# SIMG301M104LIH register map
Vendor: Silicon Labs; Series: Si; File version: B
Registers are 32-bit, read-write, reset 0x0 unless marked. A register's access mark holds for its fields unless they carry their own. Offsets are from the block's base; [hi:lo] are bit positions.

## LPWAES_NS — LPWAES_NS Registers
Base 0x41004000
Same registers: SYMCRYPTO_NS 0x41000000, SYMCRYPTO_S 0x51000000, LPWAES_S 0x51004000
0x00 FETCHADDR — Fetcher: Start address of data block. In direct mode, this register is written by the software. In scatter-gather mode, this register is updated after each processed descriptor.
  [31:0] ADDR — Start address of data block
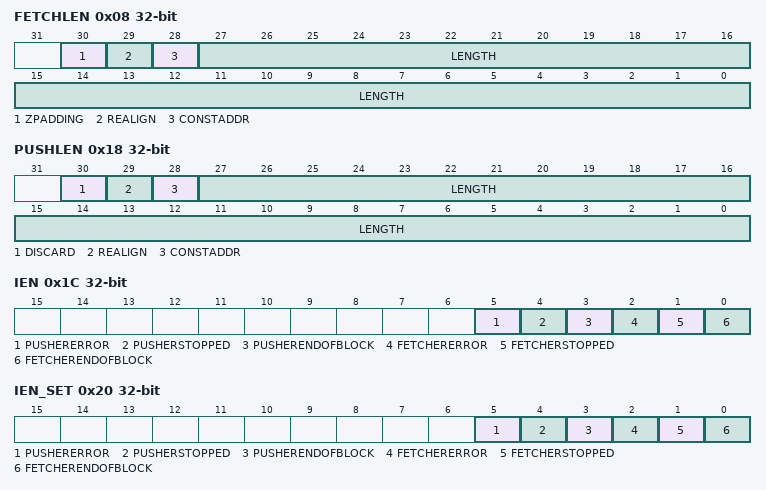
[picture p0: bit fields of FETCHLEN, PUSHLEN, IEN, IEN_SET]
0x08 FETCHLEN — Fetcher: Length of data block. In direct mode, this register is written by the software. In scatter-gather mode, this register is not used.
  [30] ZPADDING — Generate zeroes
  [29] REALIGN — Realign lengh
  [28] CONSTADDR — Constant address
  [27:0] LENGTH — Length of data block
0x0C FETCHTAG — Fetcher: User tag. In direct mode, this register is written by the software. In scatter-gather mode, this register is not used.
  [31:0] TAG — User tag
0x10 PUSHADDR — Pusher: Start address of data block (LSB). In direct mode, this register is written by the software. In scatter-gather mode, this register is updated after each processed descriptor.
  [31:0] ADDR — Start address of data block
0x18 PUSHLEN — Pusher: Length of data block. In direct mode, this register is written by the software. In scatter-gather mode, this register is not used.
  [30] DISCARD — Discard data
  [29] REALIGN — Realign length
  [28] CONSTADDR — Constant address
  [27:0] LENGTH — Start address of data block
0x1C IEN — Interrupt enable
  [5] PUSHERERROR — Error interrupt enable
  [4] PUSHERSTOPPED — Stopped interrupt enable
  [3] PUSHERENDOFBLOCK — End of block interrupt enable
  [2] FETCHERERROR — Error interrupt enable
  [1] FETCHERSTOPPED — Stopped interrupt enable
  [0] FETCHERENDOFBLOCK — End of block interrupt enable
0x20 IEN_SET wo — Set register for IEN. Writing a '1' enables the interrupt. Writing a '0' has no effect.
  [5] PUSHERERROR — Error interrupt enable set
  [4] PUSHERSTOPPED — Stopped interrupt enable set
  [3] PUSHERENDOFBLOCK — End of block interrupt enable set
  [2] FETCHERERROR — Error interrupt enable set
  [1] FETCHERSTOPPED — Stopped interrupt enable set
  [0] FETCHERENDOFBLOCK — End of block interrupt enable set
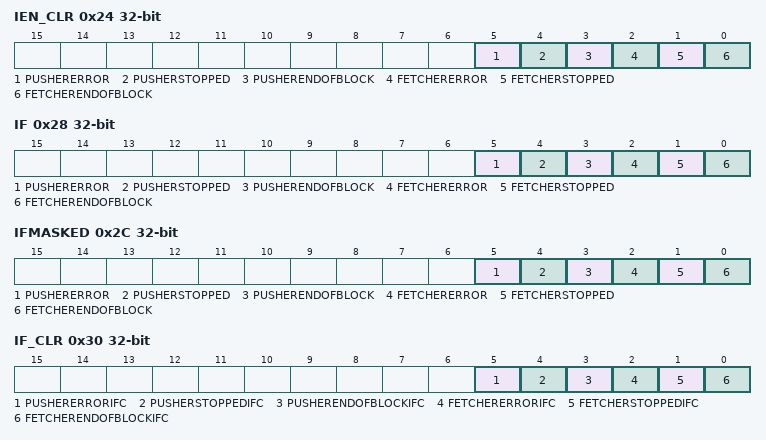
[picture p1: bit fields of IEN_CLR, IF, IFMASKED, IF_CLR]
0x24 IEN_CLR wo — Clear register for IEN. Writing a '1' enables the interrupt. Writing a '0' has no effect.
  [5] PUSHERERROR — Error interrupt enable clear
  [4] PUSHERSTOPPED — Stopped interrupt enable clear
  [3] PUSHERENDOFBLOCK — End of block interrupt enable clear
  [2] FETCHERERROR — Error interrupt enable clear
  [1] FETCHERSTOPPED — Stopped interrupt enable clear
  [0] FETCHERENDOFBLOCK — End of block interrupt enable clear
0x28 IF ro — Interrupt flag register
  [5] PUSHERERROR — Error interrupt flag
  [4] PUSHERSTOPPED — Stopped interrupt flag
  [3] PUSHERENDOFBLOCK — End of block interrupt flag
  [2] FETCHERERROR — Error interrupt flag
  [1] FETCHERSTOPPED — Stopped interrupt flag
  [0] FETCHERENDOFBLOCK — End of block interrupt flag
0x2C IFMASKED ro — Reading returns the interrupt status masked by IEN.
  [5] PUSHERERROR — Error interrupt flag masked
  [4] PUSHERSTOPPED — Stopped interrupt flag masked
  [3] PUSHERENDOFBLOCK — End of block interrupt flag masked
  [2] FETCHERERROR — Error interrupt flag masked
  [1] FETCHERSTOPPED — Stopped interrupt flag masked
  [0] FETCHERENDOFBLOCK — End of block interrupt flag masked
0x30 IF_CLR wo — Writing a '1' clears the interrupt status. Writing a '0' has no effect.
  [5] PUSHERERRORIFC — Error interrupt flag clear
  [4] PUSHERSTOPPEDIFC — Stopped interrupt flag clear
  [3] PUSHERENDOFBLOCKIFC — End of block interrupt flag clear
  [2] FETCHERERRORIFC — Error interrupt flag clear
  [1] FETCHERSTOPPEDIFC — Stopped interrupt flag clear
  [0] FETCHERENDOFBLOCKIFC — End of block interrupt flag clear
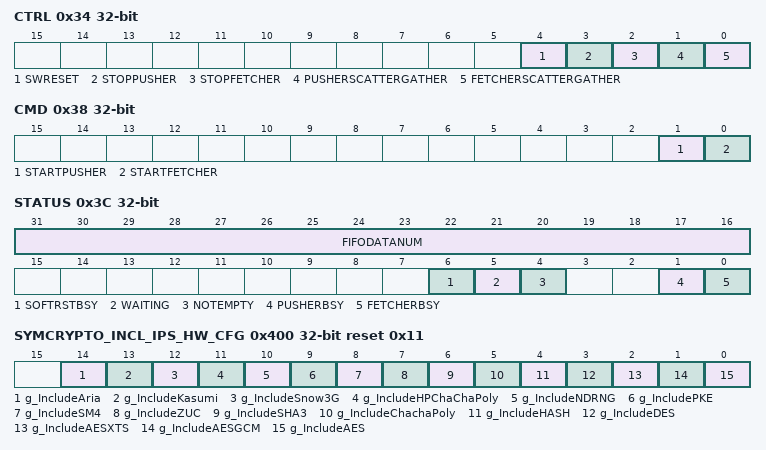
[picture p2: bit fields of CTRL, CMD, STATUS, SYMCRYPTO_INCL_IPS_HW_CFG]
0x34 CTRL — Control register, called CONFIG in Barco datasheet.
  [4] SWRESET — Software reset
  [3] STOPPUSHER
  [2] STOPFETCHER
  [1] PUSHERSCATTERGATHER
  [0] FETCHERSCATTERGATHER
0x38 CMD wo — Command register for starting the fetcher and pusher
  [1] STARTPUSHER — Start push
  [0] STARTFETCHER — Start fetch
0x3C STATUS ro
  [31:16] FIFODATANUM — Number of data in output FIFO
  [6] SOFTRSTBSY — Software reset busy
  [5] WAITING — Pusher waiting for FIFO
  [4] NOTEMPTY — Not empty flag from input FIFO (fetcher)
  [1] PUSHERBSY — Pusher busy
  [0] FETCHERBSY — Fetcher busy
0x400 SYMCRYPTO_INCL_IPS_HW_CFG ro reset 0x11
  [14] g_IncludeAria — Includes Aria
  [13] g_IncludeKasumi — Includes Kasumi
  [12] g_IncludeSnow3G — Includes Snow3G
  [11] g_IncludeHPChaChaPoly — Includes HP-ChaChaPoly
  [10] g_IncludeNDRNG — Includes NDRNG
  [9] g_IncludePKE — Includes PKE
  [8] g_IncludeSM4 — Includes SM4
  [7] g_IncludeZUC — Includes ZUC
  [6] g_IncludeSHA3 — Includes SHA3
  [5] g_IncludeChachaPoly — Includes ChachaPoly
  [4] g_IncludeHASH — Includes HASH
  [3] g_IncludeDES — Includes DES
  [2] g_IncludeAESXTS — Includes AESXTS
  [1] g_IncludeAESGCM — Includes AESGCM
  [0] g_IncludeAES — Includes AES
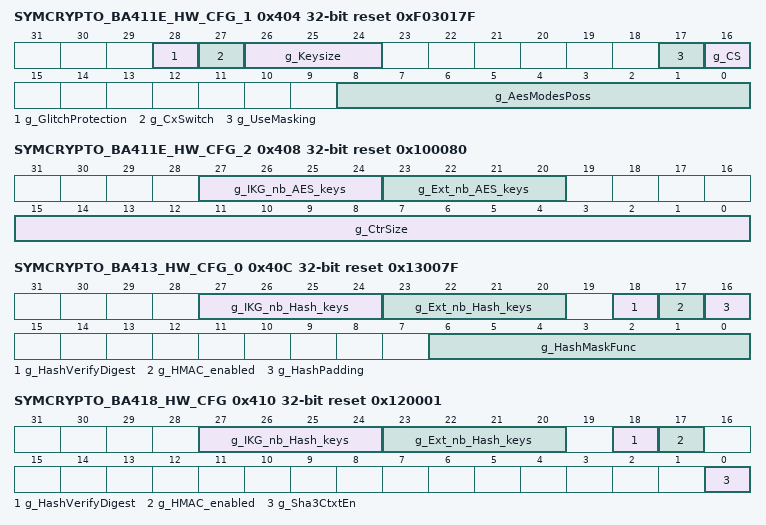
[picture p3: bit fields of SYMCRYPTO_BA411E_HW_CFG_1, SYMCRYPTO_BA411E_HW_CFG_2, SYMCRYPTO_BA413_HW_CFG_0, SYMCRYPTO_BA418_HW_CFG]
0x404 SYMCRYPTO_BA411E_HW_CFG_1 ro reset 0xF03017F
  [28] g_GlitchProtection — Generic g_GlitchProtection value
  [27] g_CxSwitch — Generic g_CxSwitch value
  [26:24] g_Keysize — Generic g_Keysize value
  [17] g_UseMasking — Generic g_UseMasking value
  [16] g_CS — Generic g_CS value
  [8:0] g_AesModesPoss — AES Modes Supported
0x408 SYMCRYPTO_BA411E_HW_CFG_2 ro reset 0x100080
  [27:24] g_IKG_nb_AES_keys — Generic g_IKG_nb_AES_keys
  [23:20] g_Ext_nb_AES_keys — Generic g_Ext_nb_AES_keys
  [15:0] g_CtrSize — Generic g_CtrSize value
0x40C SYMCRYPTO_BA413_HW_CFG_0 ro reset 0x13007F
  [27:24] g_IKG_nb_Hash_keys — Generic g_IKG_nb_Hash_keys value
  [23:20] g_Ext_nb_Hash_keys — Generic g_Ext_nb_Hash_keys value
  [18] g_HashVerifyDigest — Generic g_HashVerifyDigest value
  [17] g_HMAC_enabled — Generic g_HMAC_enabled value
  [16] g_HashPadding — Generic g_HashPadding value
  [6:0] g_HashMaskFunc — Generic g_HashMaskFunc value
0x410 SYMCRYPTO_BA418_HW_CFG ro reset 0x120001
  [27:24] g_IKG_nb_Hash_keys — Generic g_IKG_nb_Hash_keys value
  [23:20] g_Ext_nb_Hash_keys — Generic g_Ext_nb_Hash_keys value
  [18] g_HashVerifyDigest — Generic g_HashVerifyDigest value
  [17] g_HMAC_enabled — Generic g_HMAC_enabled value
  [0] g_Sha3CtxtEn — Generic g_Sha3CtxtEn value
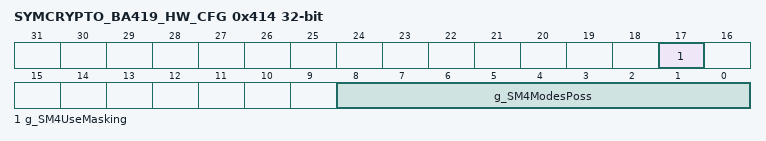
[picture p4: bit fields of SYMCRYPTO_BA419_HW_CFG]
0x414 SYMCRYPTO_BA419_HW_CFG ro
  [17] g_SM4UseMasking — Generic g_SM4UseMasking value
  [8:0] g_SM4ModesPoss — Generic g_SM4ModesPoss value
0x418 SYMCRYPTO_BA424_HW_CFG ro
  [8:0] g_aria_modePoss — Generic g_aria_modePoss value
